AUTOSAR XML (schema 4-2-2)
package /AUTOSAR/Components
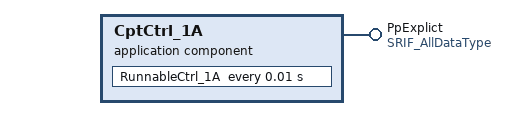
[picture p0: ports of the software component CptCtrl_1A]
  application sw component type CptCtrl_1A
    provide port PpExplict: provided-interface=SRIF_AllDataType
    behavior IbCtrl_1A
      timing event timingEvent_10: start-on-event=RunnableCtrl_1A, period=0.01
      runnable RunnableCtrl_1A: symbol=AppRunnableCtrl_1A
        data-send-points:
          access dataSendPointsStruct: accessed-variable=PpExplict.dataElementStruct
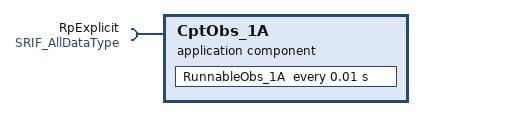
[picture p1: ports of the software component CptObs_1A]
  application sw component type CptObs_1A
    require port RpExplicit: required-interface=SRIF_AllDataType
      required-com-specs:
        data-element=dataElementPrimitive, external-replacement=dataElementPrimitive, init-value=0
        data-element=dataElementStruct, init-value=fields=[0, 1, 2]
        data-element=dataElementArray, init-value=[0]
    behavior IbObs_1A
      timing event timingEvent_10: start-on-event=RunnableObs_1A, period=0.01
      runnable RunnableObs_1A: reentrancy-level=SINGLE-CORE-REENTRANT, symbol=AppRunnableObs_1A
        data-receive-point-by-arguments:
          access DataReceiveByArgPrimitive: accessed-variable=RpExplicit.dataElementPrimitive
          access DataReceiveByArgArray: accessed-variable=RpExplicit.dataElementArray
          access DataReceiveByArgStruct: accessed-variable=RpExplicit.dataElementStruct
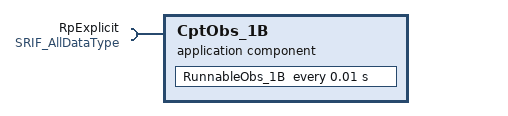
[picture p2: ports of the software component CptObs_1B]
  application sw component type CptObs_1B
    require port RpExplicit: nonqueued-receiver-com-spec{data-element=dataElementStruct, init-value=fields=[0, 1, 2]}, required-interface=SRIF_AllDataType
    behavior IbObs_1B
      timing event timingEvent_10: start-on-event=RunnableObs_1B, period=0.01
      runnable RunnableObs_1B: symbol=AppRunnableObs_1B
        data-receive-point-by-arguments:
          access DataReceiveByArgStruct: accessed-variable=RpExplicit.dataElementStruct
